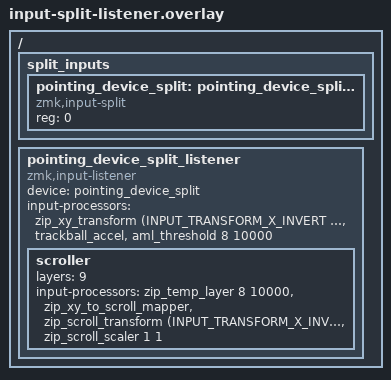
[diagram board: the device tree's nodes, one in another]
/{
    split_inputs {
        #address-cells = <1>;
        #size-cells = <0>;

        pointing_device_split: pointing_device_split@0 {
            compatible = "zmk,input-split";
            reg = <0>;
        };
    };

    pointing_device_split_listener: pointing_device_split_listener {
        compatible = "zmk,input-listener";
        device = <&pointing_device_split>;
        status = "okay";
        // AML とスクロールは右手側のボール (torabo_tsuki_lp_right.overlay の pointing_listener) と同じ
        input-processors =
            <&zip_xy_transform (INPUT_TRANSFORM_X_INVERT | INPUT_TRANSFORM_Y_INVERT)>,
            <&trackball_accel>,             // 速さに応じた倍率 (カーソルの加速)
            <&aml_threshold 8 10000>;       // 8 = MOUS (マウス移動レイヤーを自動有効化。わずかな動きでは発動しない)

        scroller {
            layers = <9>;
            input-processors =
                <&zip_temp_layer 8 10000>,  // 8 = MOUS (スクロール中も MOUS を維持する)
                <&zip_xy_to_scroll_mapper>,
                <&zip_scroll_transform (INPUT_TRANSFORM_X_INVERT)>,
                <&zip_scroll_scaler 1 1>;
        };
     };
};
